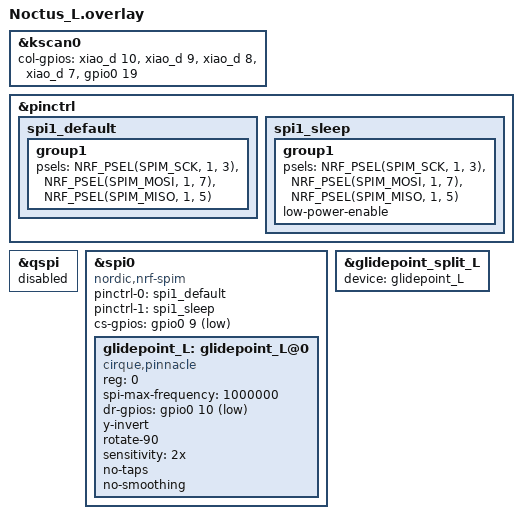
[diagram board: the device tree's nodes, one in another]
#include "Noctus.dtsi"
#include <dt-bindings/zmk/input_transform.h>
#include <input/processors.dtsi>

&kscan0 {
        col-gpios
            = <&xiao_d 10 (GPIO_ACTIVE_HIGH | GPIO_PULL_DOWN)>
            , <&xiao_d 9 (GPIO_ACTIVE_HIGH | GPIO_PULL_DOWN)>
            , <&xiao_d 8 (GPIO_ACTIVE_HIGH | GPIO_PULL_DOWN)>
            , <&xiao_d 7 (GPIO_ACTIVE_HIGH | GPIO_PULL_DOWN)>
            , <&gpio0 19 (GPIO_ACTIVE_HIGH | GPIO_PULL_DOWN)>
            ;
};

//Trackpad
&pinctrl {
    spi1_default: spi1_default {
        group1 {
            psels = <NRF_PSEL(SPIM_SCK, 1, 3)>,
                    <NRF_PSEL(SPIM_MOSI, 1, 7)>,
                    <NRF_PSEL(SPIM_MISO, 1, 5)>;
        };
    };
    spi1_sleep: spi1_sleep {
        group1 {
            psels = <NRF_PSEL(SPIM_SCK, 1, 3)>,
                    <NRF_PSEL(SPIM_MOSI, 1, 7)>,
                    <NRF_PSEL(SPIM_MISO, 1, 5)>;
            low-power-enable;
        };
    };
};

&qspi {
	status = "disabled";
};

&spi0 {
    status = "okay";
    compatible = "nordic,nrf-spim";
    pinctrl-0 = <&spi1_default>;
    pinctrl-1 = <&spi1_sleep>;
    pinctrl-names = "default", "sleep";
    cs-gpios = <&gpio0 9 GPIO_ACTIVE_LOW>;

    glidepoint_L: glidepoint_L@0 {
        status = "okay";
        compatible = "cirque,pinnacle";
        reg = <0>;
        spi-max-frequency = <1000000>;
        dr-gpios = <&gpio0 10 (GPIO_ACTIVE_LOW | GPIO_PULL_UP)>;
        y-invert;
        rotate-90;

        sensitivity = "2x";
        no-taps;
        no-smoothing;

    };
};

&glidepoint_split_L {
    device = <&glidepoint_L>;
};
